# psc3_p8_ppca register map
Vendor: Infineon Technologies; Series: PSC3_P8; File version: 1.0
CPU: CM33 r0p1, little endian, MPU, FPU, DSP, VTOR, 3 interrupt priority bits, 143 interrupts
Registers are 32-bit, read-write, reset 0x0 unless marked. A register's access mark holds for its fields unless they carry their own. Offsets are from the block's base; [hi:lo] are bit positions; lines under a group give offsets from that group; {n}, {i} and the like mark numbered series; 'fields as' and 'values as' point back to an identical list.

## MXAES
Base 0x68270000
0x00 UNMASKED_USER_RANGE group — AES command and configuration registers
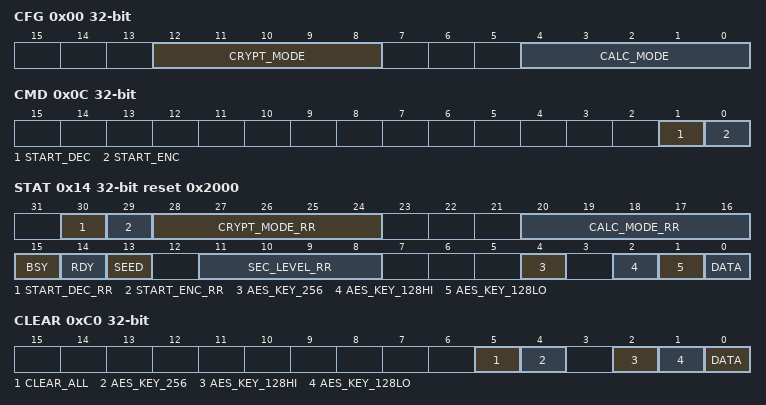
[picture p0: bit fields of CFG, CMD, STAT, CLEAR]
  0x00 CFG — AES configuration register
    [12:8] CRYPT_MODE — Cryptographic mode This field selects the key's length and key state location of the AES cryptographic engine
      0=NOMODE (No key size selection); 16=AES128LO (Set AES mode using lower half 128-bit key); 19=AES128HI (Set AES mode using higher half 128-bit key); 22=AES256 (Set AES mode using 256-bit key)
    [4:0] CALC_MODE — Mode of AES calculation This field selects the mode of operation.
      0=NOMODE (No calculation mode selected); 3=CIPHER (Set the cipher mode (corresponds to an encryption or decryption operation))
  0x0C CMD — AES command register
    [1] START_DEC write-1-clears — Launch an AES decryption operation Setting this bit launches a decryption. Any write to this bit is ignored if data is not valid and/or key for the selected key length is not valid. The bit is cleared only by hardware as soon as the flag BSY is cleared.
      0=NDEC (No decryption operation is launched); 1=DEC (A decryption operation is launched)
    [0] START_ENC write-1-clears — Launch an AES encryption operation Setting this bit launches an encryption. Any write to this bit is ignored if data is not valid and/or key for the selected key length is not valid. The bit is cleared only by hardware as soon as the flag BSY is cleared.
      0=NENC (No encryption operation is launched); 1=ENC (An encryption operation is launched)
  0x14 STAT ro reset 0x2000 — AES status register
    [30] START_DEC_RR — START_DEC reread bit This bit is set by hardware as soon as CMD.START_DEC is set by software. This bit is cleared by hardware as soon as STAT.BSY is cleared.
    [29] START_ENC_RR — START_ENC reread bit This bit is set by hardware as soon as CMD.START_ENC is set by software. This bit is cleared by hardware as soon as STAT.BSY is cleared.
    [28:24] CRYPT_MODE_RR — CRYPT_MODE reread bits
    [20:16] CALC_MODE_RR — CALC_MODE reread bits
    [15] BSY — Busy flag The busy flag indicates whether the AES engine is busy or not. Attention this flag indicates whether an encryption or decryption is undergoing or not.
      0=NBSY (Module is not busy with an AES operation); 1=BSY (Module is busy doing a cryptographic operation)
    [14] RDY — Ready flag The ready flag indicates whether the result of an operation is available. It is asserted as soon as a valid result is available. This flag is deasserted in one of the following cases: any bit in the CLEAR register is set, any data register is written, or any legal write to CFG register.
      0=AES_NRDY (Result is not ready to be read); 1=AES_RDY (Result is valid and ready to be read)
    [13] SEED — Seeding status bit Reading this bit gives the programmer the information if a seeding has been performed. Otherwise the software must write 4 words seed to the SEED_P register to seed the internal PRNG of the module. This bit is permanently set to '1' when the parameter NRNGA_INTEGRATION=1.
      1=SEED (Seeding already done); 0=NO_SEED (Seeding has not been performed yet)
    [11:8] SEC_LEVEL_RR — SEC_LEVEL reread bits
    [4] AES_KEY_256 — AES 256 Key valid
      0=A2IV (256-bit AES key has not been completely loaded); 1=A2V (256-bit AES key is valid)
    [2] AES_KEY_128HI — AES 128 High key valid
      0=AHIV (128-bit AES key high has not been completely loaded); 1=AHV (128-bit AES key high is valid)
    [1] AES_KEY_128LO — AES 128 Low key valid
      0=ALIV (128-bit AES key low has not been completely loaded); 1=ALV (128-bit AES key low is valid)
    [0] DATA — AES data valid This flag becomes valid when a complete 128-bit data block is written to the data registers.
      0=DNV (Data has not been completely loaded); 1=DV (Data is valid)
  0x60 CFG_2 — AES configuration register 2
    [3:0] SEC_LEVEL — Security level This field defines the overall security level. This feature consists of randomizing the AES execution and increases the resistance against side channel attacks targeting a key extraction as well as the strength of the backward calculation against differential fault analysis. This feature has a significant impact on the AES performance. The default value 0x0 gives the least randomization level with least performance drop impact. The security level can be increased by setting any valid values from 0x1 to 0xA) to this field. Any value greater than 0xA is evaluated as 0xA.
  0x80 INTR — AES interrupt cause register
    [0] CALC_FINISHED write-1-clears — Interrupt calculation finished This cause bit is set to 1 by hardware when the AES engine is not busy anymore with a calculation (also notified by the STAT.BSY flag). This is the unique interrupt cause of the module. This interrupt is cleared by software by either writing a 1 or by module reset or with the CLEAR_ALL bit. The software clear overrules the hardware set in case both happen simultaneously.
      1=CLEAR (Clear interrupt); 0=CLEARED (No interrupt or interrupt cleared by software or module reset)
  0x84 INTR_SET — AES interrupt set register
    [0] CALC_FINISHED write-1-sets — Interrupt set calculation finished Interrupt set bit corresponding to interrupt cause bit. This bit is readable. Only the software can set it by writing 1.
  0x8C INTR_MASK — AES interrupt mask register
    [0] CALC_FINISHED — Interrupt mask calculation finished The interrupt cause bit will only cause an interrupt when its mask bit is set.
  0x90 INTR_MASKED ro — AES masked interrupt register
    [0] CALC_FINISHED — Masked interrupt calculation finished Logical and of corresponding request and mask bits.
  0xC0 CLEAR wo — AES clear register
    [5] CLEAR_ALL — Clear all SFRs and AES internal registers Setting this bit behaves as a module reset. It clears all AES keys, data, all SFRs and all AES internal registers.
      0=NCLR (Clear is disabled); 1=CLR (A clear all is triggered)
    [4] AES_KEY_256 — Clear AES 256 Key
      1=CLR (256-bit AES key is cleared if it is set in the STAT register. This clears AES_KEY_128HI and LO keys); 0=NCLR (256-bit AES key keeps its value)
    [2] AES_KEY_128HI — Clear AES 128 High Key
      0=NCLR (128-bit AES key high keeps its value); 1=CLR (128-bit AES key high is cleared)
    [1] AES_KEY_128LO — Clear AES 128 Low Key
      0=NCLR (128-bit AES key low keeps its value); 1=CLR (128-bit AES key is cleared)
    [0] DATA — Clear data
      0=NCLR (Data keeps its value); 1=CLR (Data clearing triggered)
  0xDC BUS_COUNTER — AES Bus counter register
    [7:0] CTR — Key and data write counter The counter is incremented on every bus write access of data or key. On Debug write access of key or data registers the counter is not incremented. It is reset on module reset but never reset otherwise. When it reaches 0xFF and a key or data bus write happens, it is incremented to 0x00 while the overflow is ignored.
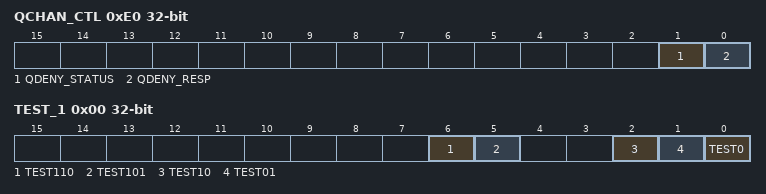
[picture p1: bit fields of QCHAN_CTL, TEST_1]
  0xE0 QCHAN_CTL — AES Q-channel control register
    [1] QDENY_STATUS write-1-clears — Q-Channel QDENY Status. This status bit allows dynamic debug when a qdeny occurs.
      0=NODENY (No quiescence request was denied); 1=DENIED (A quiescence request was denied)
    [0] QDENY_RESP — Q-Channel QDENY Response Policy. This policy bit provides SW flexibility to determine whether to assert qdeny or qaccept when qreq is asserted but the IP is not quiescent. Note: The RNG always accepts the request with a clock cycle delay. That is, the register does not have any effect and is a dummy register.
      1=ACCEPT (A quiescence request is always accepted); 0=DENY (A quiescence request may be denied)
0x800 UNMASKED_INTERNAL_RANGE group — AES data registers (x for index of shares; y for index of word)
  0x00 TEST_1 — AES test register 1
    [6] TEST110 — AES test bit 6
    [5] TEST101 — AES test bit 5
    [2] TEST10 — AES test bit 2
    [1] TEST01 — AES test bit 1
    [0] TEST0 — AES test bit 0
0x1000 MASKED_USER_RANGE group — AES key shares
  0x00 SEED_U wo — AES user seeding register
    [31:0] PRNG_SEED — Seed for internal masking Writing to this register triggers the internal seeding of the PRNG mask generator of AES. The content of this register is used to seed the AES mask generator in addition to the NRNGA internal noise source. It does not reset the PRNG, it actually adds up entropy to the entropy of the NRNGA internal noise source. This register is not readable however writable at any time also during STAT.BSY status.
  0x100 KEY_0_0 wo — AES share 0 word 0 key register
    [31:0] KEY — AES key_x_y register (x for index of shares; y for index of word)
  0x10C KEY_0_1 wo — The key registers are write only and reads trigger a BusError. When the module is busy (STAT.BSY = BSY) writes to the register also trigger a BusError.
    fields as MASKED_USER_RANGE.KEY_0_0
  {0x100+0xC*j} KEY_0_{j} wo (j=2..7) — AES share 0 word {j} key register
    fields as MASKED_USER_RANGE.KEY_0_0
  {0x160+0xC*j} KEY_1_{j} wo (j=0..6) — AES share 1 word {j} key register
    fields as MASKED_USER_RANGE.KEY_0_0
  0x1B4 KEY_1_7 wo — AES share 1 word 7 data register
    fields as MASKED_USER_RANGE.KEY_0_0
  {0x400+0xC*j} DATA_0_{j} (j=0..3) — AES share 0 word {j} data register
    [31:0] DATA — AES data_x_y register (x for index of shares; y for index of word)
  {0x430+0xC*j} DATA_1_{j} (j=0..3) — AES share 1 word {j} data register
    fields as MASKED_USER_RANGE.DATA_0_0
  {0x490+0xC*j} DATA_RR_0_{j} ro (j=0..3) — AES share 0 word {j} data reread register
    [31:0] DATA — AES data reread register (data_rr_x_y: x for index of shares; y for index of word)
  {0x4C0+0xC*j} DATA_RR_1_{j} ro (j=0..3) — AES share 1 word {j} data reread register
    fields as MASKED_USER_RANGE.DATA_RR_0_0
0x1800 MASKED_INTERNAL_RANGE group — AES Internal registers
  0x00 TEST_2 wo — AES second test register
    [31:0] TEST — Test bits
